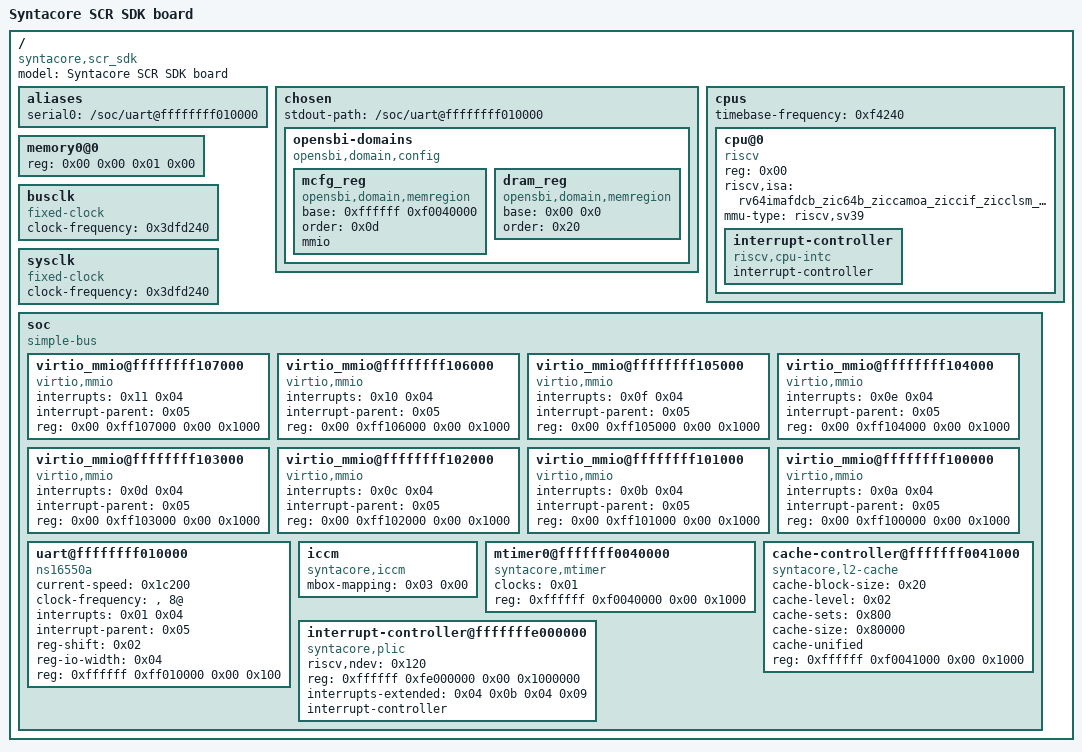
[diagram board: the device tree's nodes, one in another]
/dts-v1/;

/ {
	#address-cells = <0x02>;
	#size-cells = <0x02>;
	compatible = "syntacore,scr_sdk";
	model = "Syntacore SCR SDK board";

	aliases {
		serial0 = "/soc/uart@ffffffff010000";
	};

	chosen {
		stdout-path = "/soc/uart@ffffffff010000";

		opensbi-domains {
			compatible = "opensbi,domain,config";

			mcfg_reg: mcfg_reg {
				compatible = "opensbi,domain,memregion";
				base = <0xffffff 0xf0040000>;
				order = <0x0d>;
				mmio;
			};

			dram_reg: dram_reg {
				compatible = "opensbi,domain,memregion";
				base = <0x00 0x0>;
				order = <0x20>;
			};
		};
	};

	cpus {
		#address-cells = <0x01>;
		#size-cells = <0x00>;
		timebase-frequency = <0xf4240>;

		cpu@0 {
			device_type = "cpu";
			reg = <0x00>;
			status = "okay";
			compatible = "riscv";
			riscv,isa = "rv64imafdcb_zic64b_ziccamoa_ziccif_zicclsm_ziccrse_zicntr_zicsr_zifencei_zihpm_zmmul_za64rs_zaamo_zalrsc_zca_zcd_zba_zbb_zbc_zbkb_zbkc_zbkx_zbs_zkn_zknd_zkne_zknh_zksed_zksh_zkt_shcounterenw_shgatpa_shtvala_shvsatpa_shvstvala_shvstvecd_ssccptr_sscounterenw_sstvala_sstvecd_ssu64xl_xsyntacore";
			mmu-type = "riscv,sv39";
			phandle = <0x03>;

			interrupt-controller {
				#interrupt-cells = <0x01>;
				interrupt-controller;
				compatible = "riscv,cpu-intc";
				phandle = <0x04>;
			};
		};
	};

	memory0@0 {
		device_type = "memory";
		reg = <0x00 0x00 0x01 0x00>;
	};

	busclk {
		#clock-cells = <0x00>;
		compatible = "fixed-clock";
		clock-frequency = <0x3dfd240>;
		phandle = <0x02>;
	};

	sysclk {
		#clock-cells = <0x00>;
		compatible = "fixed-clock";
		clock-frequency = <0x3dfd240>;
		phandle = <0x01>;
	};

	soc {
		#address-cells = <0x02>;
		#size-cells = <0x02>;
		compatible = "simple-bus";
		ranges;

		virtio_mmio@ffffffff107000 {
			interrupts = <0x11 0x04>;
			interrupt-parent = <0x05>;
			reg = <0x00 0xff107000 0x00 0x1000>;
			compatible = "virtio,mmio";
		};

		virtio_mmio@ffffffff106000 {
			interrupts = <0x10 0x04>;
			interrupt-parent = <0x05>;
			reg = <0x00 0xff106000 0x00 0x1000>;
			compatible = "virtio,mmio";
		};

		virtio_mmio@ffffffff105000 {
			interrupts = <0x0f 0x04>;
			interrupt-parent = <0x05>;
			reg = <0x00 0xff105000 0x00 0x1000>;
			compatible = "virtio,mmio";
		};

		virtio_mmio@ffffffff104000 {
			interrupts = <0x0e 0x04>;
			interrupt-parent = <0x05>;
			reg = <0x00 0xff104000 0x00 0x1000>;
			compatible = "virtio,mmio";
		};

		virtio_mmio@ffffffff103000 {
			interrupts = <0x0d 0x04>;
			interrupt-parent = <0x05>;
			reg = <0x00 0xff103000 0x00 0x1000>;
			compatible = "virtio,mmio";
		};

		virtio_mmio@ffffffff102000 {
			interrupts = <0x0c 0x04>;
			interrupt-parent = <0x05>;
			reg = <0x00 0xff102000 0x00 0x1000>;
			compatible = "virtio,mmio";
		};

		virtio_mmio@ffffffff101000 {
			interrupts = <0x0b 0x04>;
			interrupt-parent = <0x05>;
			reg = <0x00 0xff101000 0x00 0x1000>;
			compatible = "virtio,mmio";
		};

		virtio_mmio@ffffffff100000 {
			interrupts = <0x0a 0x04>;
			interrupt-parent = <0x05>;
			reg = <0x00 0xff100000 0x00 0x1000>;
			compatible = "virtio,mmio";
		};

		uart@ffffffff010000 {
			current-speed = <0x1c200>;
			clock-frequency = "", "8@";
			interrupts = <0x01 0x04>;
			interrupt-parent = <0x05>;
			reg-shift = <0x02>;
			reg-io-width = <0x04>;
			reg = <0xffffff 0xff010000 0x00 0x100>;
			compatible = "ns16550a";
		};

		iccm {
			mbox-mapping = <0x03 0x00>;
			compatible = "syntacore,iccm";
		};

		mtimer0@fffffff0040000 {
			clocks = <0x01>;
			reg = <0xffffff 0xf0040000 0x00 0x1000>;
			compatible = "syntacore,mtimer";
		};

		cache-controller@fffffff0041000 {
			cache-block-size = <0x20>;
			cache-level = <0x02>;
			cache-sets = <0x800>;
			cache-size = <0x80000>;
			cache-unified;
			reg = <0xffffff 0xf0041000 0x00 0x1000>;
			compatible = "syntacore,l2-cache", "cache";
		};

		interrupt-controller@fffffffe000000 {
			phandle = <0x05>;
			riscv,ndev = <0x120>;
			reg = <0xffffff 0xfe000000 0x00 0x1000000>;
			interrupts-extended = <0x04 0x0b 0x04 0x09>;
			interrupt-controller;
			compatible = "syntacore,plic", "sifive,plic-1.0.0", "riscv,plic0";
			#interrupt-cells = <0x02>;
		};
	};
};
